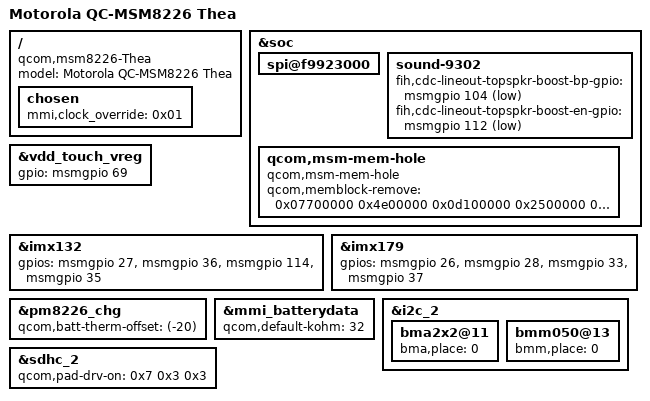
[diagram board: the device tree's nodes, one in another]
/* Copyright (c) 2014, Motorola Mobility LLC. All rights reserved.
 *
 * This program is free software; you can redistribute it and/or modify
 * it under the terms of the GNU General Public License version 2 and
 * only version 2 as published by the Free Software Foundation.
 *
 * This program is distributed in the hope that it will be useful,
 * but WITHOUT ANY WARRANTY; without even the implied warranty of
 * MERCHANTABILITY or FITNESS FOR A PARTICULAR PURPOSE.  See the
 * GNU General Public License for more details.
 */

/include/ "msm8226-titan-common.dtsi"
/include/ "msm8226-v1-pm.dtsi"
/include/ "msm8926-thea-gpiomux.dtsi"

/ {
	model = "Motorola QC-MSM8226 Thea";
	compatible = "qcom,msm8226-Thea",
		     "qcom,msm8226-moto",
		     "qcom,msm8226";
};

&soc {

	spi@f9923000 {
		/delete-node/ nmi326@0; /* Remove DTV */
	};

	sound-9302 {
		fih,cdc-lineout-topspkr-boost-bp-gpio = <&msmgpio 104 0x1>;
		fih,cdc-lineout-topspkr-boost-en-gpio = <&msmgpio 112 0x1>;
	};
        qcom,msm-mem-hole {
                compatible = "qcom,msm-mem-hole";
                qcom,memblock-remove = <0x07700000 0x4e00000
					0x0d100000 0x2500000
                                        0x0fa00000 0x500000>; /* Address and size of the hole */
        };

};

&vdd_touch_vreg {
	/delete-property/ gpio;
	gpio = <&msmgpio 69 0x0>;
};

&imx132 {
	/delete-property/ gpios;
	gpios = <&msmgpio 27 0>,
		<&msmgpio 36 0>,
		<&msmgpio 114 0>,
		<&msmgpio 35 0>;
};

&imx179 {
	/delete-property/ gpios;
	gpios = <&msmgpio 26 0>,
		<&msmgpio 28 0>,
		<&msmgpio 33 0>,
		<&msmgpio 37 0>;
};

&pm8226_chg {
	qcom,batt-therm-offset = <(-20)>;
};

&mmi_batterydata {
	qcom,default-kohm = <32>;

	/delete-node/ mmi,ed30-temp-batterydata;
	/delete-node/ mmi,ed30-sony-batterydata;
	/delete-node/ mmi,ed30-sony-batterydata-alt;
	/delete-node/ mmi,ed30-lg-batterydata;

	/include/ "batterydata-ft40-lg.dtsi"
	/include/ "batterydata-ft40-sony.dtsi"
	/include/ "batterydata-ft40-lishen.dtsi"
};

&i2c_2 {
	bma2x2@11 {
		/delete-property/ bma,place;
		bma,place = <0>;
	};

	bmm050@13 {
		/delete-property/ bmm,place;
		bmm,place = <0>;
	};
};

/ {
	chosen {
		mmi,clock_override = <0x01>;
	};
};
&sdhc_2 {
	qcom,pad-drv-on = <0x7 0x3 0x3>;  /* 16mA, 8mA, 8mA */
};
